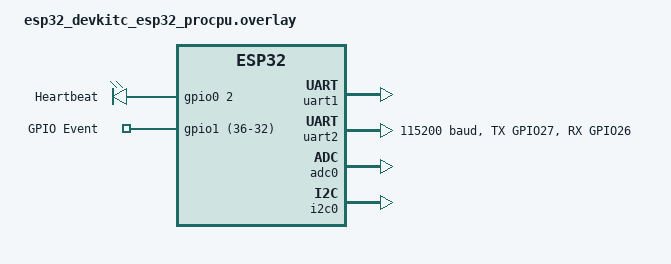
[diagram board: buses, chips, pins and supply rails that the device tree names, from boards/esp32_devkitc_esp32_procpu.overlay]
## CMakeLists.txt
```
# SPDX-License-Identifier: Apache-2.0

cmake_minimum_required(VERSION 3.20.0)

# DTC_OVERLAY_FILE must be set BEFORE find_package.
# Board-specific overlays in boards/ are picked up automatically by Zephyr.
# Add module overlays here.

# BOARD is not yet defined before find_package in sysbuild context,
# so we glob board overlays instead of relying on ${BOARD}.
file(GLOB BOARD_OVERLAYS "${CMAKE_CURRENT_SOURCE_DIR}/boards/*.overlay")

set(DTC_OVERLAY_FILE
  "${CMAKE_CURRENT_SOURCE_DIR}/app.overlay"
  ${BOARD_OVERLAYS}
  "${CMAKE_CURRENT_SOURCE_DIR}/drivers/sensor/voltage_monitor/vmon.dtsi"
)

# Local secrets (Wi-Fi credentials, etc.) — NOT tracked by git.
# Create prj_local.conf if you need to override placeholders.
if(EXISTS "${CMAKE_CURRENT_SOURCE_DIR}/prj_local.conf")
  set(OVERLAY_CONFIG "${CMAKE_CURRENT_SOURCE_DIR}/prj_local.conf")
endif()

find_package(Zephyr REQUIRED HINTS $ENV{ZEPHYR_BASE})
project(my_app)

# Custom DTS bindings (must be after find_package for bindings, but DTS_ROOT
# also used for preprocessor — we rely on DTC_OVERLAY_FILE for module DTS)
set(DTS_ROOT ${CMAKE_CURRENT_SOURCE_DIR})

target_sources(app PRIVATE src/main.c)
target_sources(app PRIVATE src/uart_comm/uart_comm.c)
target_sources(app PRIVATE src/gpio_event/gpio_event.c)
target_sources(app PRIVATE src/image_update/image_update.c)
target_sources(app PRIVATE src/image_update/self_copy.c)
target_sources(app PRIVATE src/image_update/slot_selector.c)

target_sources_ifdef(CONFIG_APP_WIFI_LOG app PRIVATE
  drivers/wifi_log/wifi_log.c
)

# Sensors
target_sources(app PRIVATE
  drivers/sensor/voltage_monitor/voltage_monitor.c
)

target_include_directories(app PRIVATE include)
```

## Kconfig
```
# SPDX-License-Identifier: Apache-2.0
#
# Application Kconfig for my_app.
#
rsource "drivers/Kconfig"
# Future: rsource "lib/Kconfig"

source "Kconfig.zephyr"

menu "my_app Configuration"

config APP_SYSTEM_INFO_INTERVAL
	int "System info print interval (iterations)"
	default 10
	range 1 3600
	help
	  Print extended system information every N trace iterations.

config APP_LOOP_PERIOD_MS
	int "Main loop period (ms)"
	default 1000
	help
	  Main loop sleep interval in milliseconds.

config APP_I2C_POLL_MS
	int "I2C poll interval (ms)"
	default 500
	help
	  How often to poll the I2C slave.

endmenu
```

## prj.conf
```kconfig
# SPDX-License-Identifier: Apache-2.0
#
# Application Kconfig defaults.
# See Kconfig (menu "my_app Configuration") for all app-level options.

# UART console (obtained from Devicetree chosen node)
CONFIG_CONSOLE=y
CONFIG_SERIAL=y
CONFIG_UART_CONSOLE=y

# Logging subsystem — outputs trace over UART via LOG backend
CONFIG_LOG=y
CONFIG_LOG_MODE_IMMEDIATE=y
CONFIG_LOG_BACKEND_UART=y

# Wi-Fi
CONFIG_WIFI=y
CONFIG_WIFI_ESP32=y

# Network stack
CONFIG_NETWORKING=y
CONFIG_NET_IPV4=y
CONFIG_NET_TCP=y
CONFIG_NET_SOCKETS=y
CONFIG_NET_DHCPV4=y
CONFIG_NET_MGMT_EVENT=y
CONFIG_NET_MGMT_EVENT_INFO=y


# ADC (required by VMON_BACKEND_ADC)
CONFIG_ADC=y
CONFIG_VMON_BACKEND_ADC=n

# I2C (required by VMON_BACKEND_I2C)
CONFIG_I2C=y
CONFIG_VMON_BACKEND_I2C=y

# I2C: 2 bytes, value already in mV
CONFIG_VMON_I2C_READ_BYTES=2
CONFIG_VMON_I2C_SCALE_NUM=1
CONFIG_VMON_I2C_SCALE_DEN=1

# Sensor subsystem
CONFIG_SENSOR=y

# DNS resolver (optional — for resolving hostnames)
CONFIG_DNS_RESOLVER=y

# my_app Wi-Fi log driver
CONFIG_APP_WIFI_LOG=y
CONFIG_APP_WIFI_LOG_SSID="your_wifi_ssid"
CONFIG_APP_WIFI_LOG_PSK="your_wifi_password"
CONFIG_APP_WIFI_LOG_SERVER_IP="192.168.50.162"
CONFIG_APP_WIFI_LOG_SERVER_PORT=5555

# Flash map and OTA — needed for slot0→slot1 self-copy
CONFIG_FLASH=y
CONFIG_FLASH_MAP=y
CONFIG_STREAM_FLASH=y
CONFIG_MPU_ALLOW_FLASH_WRITE=y
CONFIG_REBOOT=y
CONFIG_IMG_MANAGER=y
CONFIG_MCUBOOT_IMG_MANAGER=y
CONFIG_BOOTLOADER_MCUBOOT=y


CONFIG_BOOTLOADER_MCUBOOT=y
CONFIG_UART_INTERRUPT_DRIVEN=y
```

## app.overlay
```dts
/*
 * SPDX-License-Identifier: Apache-2.0
 *
 * Application-level Devicetree overlay for my_app.
 *
 * Applied to ALL boards. For board-specific DT, see boards/.
 * Module DTS files are added via DTC_OVERLAY_FILE in CMakeLists.txt.
 */

/ {
	aliases {
		/*
		 * Application-level alias for the trace UART.
		 * Used by the UART trace driver via DT_ALIAS(trace_uart).
		 */
		trace-uart = &uart0;
	};
};
```

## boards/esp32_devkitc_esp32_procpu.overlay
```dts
/*
 * SPDX-License-Identifier: Apache-2.0
 *
 * Board-specific Devicetree overlay for ESP32-DevKitC PROCPU.
 */

#include "../dts/partitions_4m.dtsi"

/* Ensure the BOOT button GPIO is enabled for this board */

&pinctrl {
	uart2_pins: uart2_pins {
		group1 {
			pinmux = <UART2_TX_GPIO27>;
		};

		group2 {
			pinmux = <UART2_RX_GPIO26>;
			bias-pull-up;
		};
	};
};

&gpio0 {
	status = "okay";
};

&uart1 {
	status = "okay";
};

&gpio1 {
	status = "okay";
};

&uart2 {
	status = "okay";
	current-speed = <115200>;
	pinctrl-0 = <&uart2_pins>;
};

&adc0 { status = "okay"; };
&i2c0 { status = "okay"; };


 / {
	chosen {
		zephyr,console = &uart1;
		zephyr,code-partition = &slot0_partition;
	};

	leds {
		compatible = "gpio-leds";
		led0: led_0 {
			gpios = <&gpio0 2 GPIO_ACTIVE_HIGH>;
			label = "Heartbeat";
		};
	};

	gpio-event {
		 compatible = "gpio-keys";
		 gpio_event0: gpio_event_0 {
			gpios = <&gpio1 (36-32) (GPIO_ACTIVE_HIGH | GPIO_PULL_DOWN)>;
			label = "GPIO Event";
		 };
	};
};
```

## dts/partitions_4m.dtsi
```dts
/*
 * SPDX-License-Identifier: Apache-2.0
 *
 * Shared flash partition layout for ESP32-DevKitC with MCUboot (4 MB).
 *
 * Included by both the board overlay (my_app image) and the sysbuild
 * mcuboot overlay so both images agree on flash geometry.
 *
 * Removes unused vendor AMP partitions (APPCPU, LPCORE, scratch,
 * coredump) and defines only what a single PROCPU image needs.
 */

/* ── Remove vendor AMP slots ──────────────────────────────────────── */

/delete-node/ &boot_partition;
/delete-node/ &sys_partition;
/delete-node/ &slot0_partition;
/delete-node/ &slot1_partition;
/delete-node/ &slot0_appcpu_partition;
/delete-node/ &slot1_appcpu_partition;
/delete-node/ &slot0_lpcore_partition;
/delete-node/ &slot1_lpcore_partition;
/delete-node/ &storage_partition;
/delete-node/ &scratch_partition;
/delete-node/ &coredump_partition;

/* ── Custom layout (4 MB flash) ─────────────────────────────────────
 *
 *   0x001000 ─ 0x010000   mcuboot           ( 60 KB)
 *   0x010000 ─ 0x020000   sys (PHY calib)   ( 64 KB) ← WiFi needs this
 *   0x020000 ─ 0x1F0000   image-0 / slot0   (1856 KB)
 *   0x1F0000 ─ 0x3C0000   image-1 / slot1   (1856 KB)
 *   0x3C0000 ─ 0x400000   storage           ( 256 KB)
 */

&flash0 {
	partitions {
		ranges;
		#address-cells = <1>;
		#size-cells = <1>;

		boot_partition: partition@1000 {
			compatible = "zephyr,mapped-partition";
			label = "mcuboot";
			reg = <0x1000 DT_SIZE_K(60)>;
		};

		sys_partition: partition@10000 {
			compatible = "zephyr,mapped-partition";
			label = "sys";
			reg = <0x10000 DT_SIZE_K(64)>;
		};

		slot0_partition: partition@20000 {
			compatible = "zephyr,mapped-partition";
			label = "image-0";
			reg = <0x20000 DT_SIZE_K(1856)>;
		};

		slot1_partition: partition@1f0000 {
			compatible = "zephyr,mapped-partition";
			label = "image-1";
			reg = <0x1f0000 DT_SIZE_K(1856)>;
		};

		storage_partition: partition@3c0000 {
			compatible = "zephyr,mapped-partition";
			label = "storage";
			reg = <0x3c0000 DT_SIZE_K(256)>;
		};
	};
};
```

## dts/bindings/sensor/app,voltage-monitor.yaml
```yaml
# SPDX-License-Identifier: Apache-2.0
description: Voltage monitor sensor — multi-backend (ADC, I2C)

compatible: "app,voltage-monitor"

include: base.yaml

properties:
  io-channels:
    type: phandle-array
    required: false
    description: |
      ADC channel spec. Required when CONFIG_VMON_BACKEND_ADC=y.
      Example: io-channels = <&adc0 6>;

  zephyr,gain:
    type: string
    required: false
    description: ADC gain (ADC_GAIN_1, ADC_GAIN_1_4, etc.)

  zephyr,reference:
    type: string
    required: false
    description: ADC reference (ADC_REF_INTERNAL, ADC_REF_EXTERNAL, etc.)

  zephyr,acquisition-time:
    type: int
    required: false
    description: ADC acquisition time

  zephyr,resolution:
    type: int
    required: false
    description: ADC resolution in bits

  i2c-bus:
    type: phandle
    required: false
    description: |
      I2C bus phandle. Required when CONFIG_VMON_BACKEND_I2C=y.
      Example: i2c-bus = <&i2c0>;

  i2c-addr:
    type: int
    required: false
    description: |
      I2C address. Required when CONFIG_VMON_BACKEND_I2C=y.
      Example: i2c-addr = <0x40>;
```

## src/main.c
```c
#include <zephyr/kernel.h>
#include <zephyr/logging/log.h>
#include <zephyr/drivers/sensor.h>
#include <zephyr/drivers/gpio.h>
#include <string.h>

#include "uart_comm/uart_comm.h"
#include "gpio_event/gpio_event.h"

#define DUAL_LOG_TAG "main"
#include <app/wifi_log.h>
#include <app/slot_selector.h>
#include <app/image_update.h>

LOG_MODULE_REGISTER(my_app, LOG_LEVEL_DBG);

static const struct gpio_dt_spec led = GPIO_DT_SPEC_GET(DT_NODELABEL(led0), gpios);
static const struct device *voltage_monitor = DEVICE_DT_GET(DT_NODELABEL(vmon));
static const struct device *uart_communicator = DEVICE_DT_GET(DT_NODELABEL(uart2));

static volatile uint32_t gpio_event_trigger_count;

static void gpio_event_handler(void)
{
	gpio_event_trigger_count++;
	log_dual_inf("[GPIO_EVENT] trigger #%u", gpio_event_trigger_count);
}

static void voltage_monitor_print(const struct device *device)
{
	struct sensor_value sensor_value;
	int error;

	error = sensor_sample_fetch(device);

	if (0 != error)
	{
		log_dual_err("Voltage monitor fetch failed: %d", error);
		return;
	}

	sensor_channel_get(device, SENSOR_CHAN_VOLTAGE, &sensor_value);

	if (0xFFFF == sensor_value.val2)
	{
		log_dual_inf("[VMON] %d mV", sensor_value.val1);
	}
	else
	{
		log_dual_inf("[VMON] %d.%03d V  (%d mV)",
			     sensor_value.val1, sensor_value.val2 / 1000,
			     sensor_value.val1 * 1000 + sensor_value.val2 / 1000);
	}
}

static void print_system_info(void)
{
	log_dual_inf("--- System Info ---");
	log_dual_inf("Board   : %s", CONFIG_BOARD);
	log_dual_inf("CPU freq: %u Hz", sys_clock_hw_cycles_per_sec());
	log_dual_inf("Uptime  : %lld ms", k_uptime_get());
	log_dual_inf("Firmware: %s %s", __DATE__, __TIME__);
	log_dual_inf("--------------------");
}

static void on_uart_line(const uint8_t *data, size_t length, void *context)
{
	(void)context;

	log_dual_inf("UART RX [%d]: %.*s", (int)length, (int)length, data);

	uart_comm_send(data, length);
	uart_comm_send((const uint8_t *)"\r\n", 2);
}

int main(void)
{
	uint32_t tick;
	uint32_t boot_source;
	int error;

	tick = 0;

	boot_source = slot_selector_boot_source_read();

	if ((0 != boot_source) && (1 != boot_source))
	{
		boot_source = 0;
		slot_selector_boot_source_write(0);
	}

	log_dual_inf("========================================");
	log_dual_inf("  my_app — Zephyr Trace Application");
	log_dual_inf("  Target: " CONFIG_BOARD);
	log_dual_inf("  Boot slot: %u", boot_source);
	log_dual_inf("========================================");

	log_dual_dbg("Debug trace enabled");
	print_system_info();

	if (false == device_is_ready(voltage_monitor))
	{
		log_dual_err("Voltage monitor not ready");
	}
	else
	{
		log_dual_inf("Voltage monitor ready");
	}

	if (false == gpio_is_ready_dt(&led))
	{
		log_dual_err("LED not ready");
	}
	else
	{
		gpio_pin_configure_dt(&led, GPIO_OUTPUT_INACTIVE);
	}

	error = wifi_log_init();
	
	if (0 > error)
	{
		log_dual_err("Wi-Fi init: %d", error);
	}

	image_update_perform(boot_source);

	if (false == device_is_ready(uart_communicator))
	{
		log_dual_err("UART communicator not ready");
	}
	else
	{
		uart_comm_set_rx_callback(on_uart_line, NULL);
		uart_comm_init(uart_communicator);
	}

	error = gpio_event_initialize(gpio_event_handler);

	if (0 != error)
	{
		log_dual_err("GPIO event init failed: %d", error);
	}

	while (1)
	{
		tick++;

		gpio_pin_toggle_dt(&led);

		uart_comm_poll();

		if (0 == (tick % (1000 / CONFIG_APP_LOOP_PERIOD_MS)))
		{
			voltage_monitor_print(voltage_monitor);
		}

		if (0 == (tick % CONFIG_APP_SYSTEM_INFO_INTERVAL))
		{
			log_dual_wrn("Snapshot #%u", tick);
			print_system_info();
		}

		k_sleep(K_MSEC(CONFIG_APP_LOOP_PERIOD_MS));
	}

	return 0;
}
```
